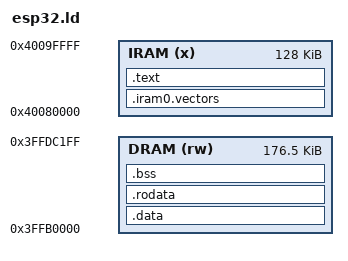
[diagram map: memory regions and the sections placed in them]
MEMORY
{
    /* Data RAM. Allows byte access. */
    DRAM  (rw) : ORIGIN = 0x3FFB0000, LENGTH = 0x2c200
    /* Instruction RAM. */
    IRAM  (x)  : ORIGIN = 0x40080000, LENGTH = 128K /* Internal SRAM 0 */
}

ENTRY(main)

SECTIONS
{
    /* Mutable global variables.
     */
    .data : ALIGN(4)
    {
        *(.data)
        *(.data.*)
    } >DRAM

    /* Constant global variables.
     */
    .rodata : ALIGN(4)
    {
        *(.rodata)
        *(.rodata.*)
    } >DRAM

    /* Global variables that are mutable and zero-initialized.
     */
    .bss (NOLOAD) : ALIGN(4)
    {
        . = ALIGN (4);
        _sbss = ABSOLUTE(.);
        *(.bss)
        *(.bss.*)
        . = ALIGN (4);
        _ebss = ABSOLUTE(.);
    } >DRAM

  .iram0.vectors :
  {
    _iram_start = ABSOLUTE(.);
    _vector_table = ABSOLUTE(.);
    . = 0x0;
    KEEP(*(.WindowVectors.text));
    . = 0x180;
    KEEP(*(.Level2InterruptVector.text));
    . = 0x1c0;
    KEEP(*(.Level3InterruptVector.text));
    . = 0x200;
    KEEP(*(.Level4InterruptVector.text));
    . = 0x240;
    KEEP(*(.Level5InterruptVector.text));
    . = 0x280;
    KEEP(*(.DebugExceptionVector.text));
    . = 0x2c0;
    KEEP(*(.NMIExceptionVector.text));
    . = 0x300;
    KEEP(*(.KernelExceptionVector.text));
    . = 0x340;
    KEEP(*(.UserExceptionVector.text));
    . = 0x3C0;
    KEEP(*(.DoubleExceptionVector.text));
    . = 0x400;
    _invalid_pc_placeholder = ABSOLUTE(.);
    *(.*Vector.literal)

    *(.UserEnter.literal);
    *(.UserEnter.text);
    . = ALIGN (16);
    *(.entry.text)
    *(.init.literal)
    *(.init)

    _init_end = ABSOLUTE(.);
  } > IRAM

    /* Constant literals and code. Loaded into IRAM for now. Eventually, most
     * code should be executed directly from flash.
     * Note that literals must be before code for the l32r instruction to work.
     */
    .text : ALIGN(4)
    {
        *(.literal .text)
        *(.literal.* .text.*)
    } >IRAM
}
